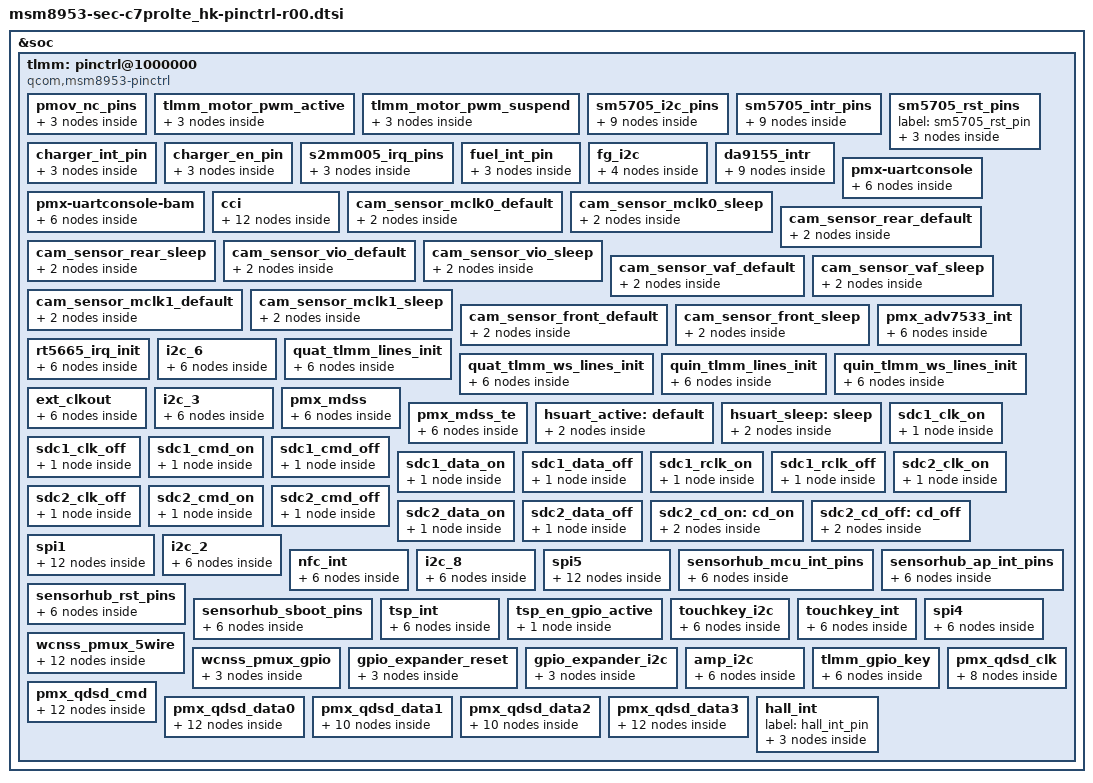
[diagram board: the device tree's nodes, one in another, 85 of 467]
/*
 * Copyright (c) 2015-2016, The Linux Foundation. All rights reserved.
 *
 * This program is free software; you can redistribute it and/or modify
 * it under the terms of the GNU General Public License version 2 and
 * only version 2 as published by the Free Software Foundation.
 *
 * This program is distributed in the hope that it will be useful,
 * but WITHOUT ANY WARRANTY; without even the implied warranty of
 * MERCHANTABILITY or FITNESS FOR A PARTICULAR PURPOSE.  See the
 * GNU General Public License for more details.
 */

&soc {
	tlmm: pinctrl@1000000 {
		compatible = "qcom,msm8953-pinctrl";
		reg = <0x1000000 0x300000>;
		interrupts = <0 208 0>;
		gpio-controller;
		#gpio-cells = <2>;
		interrupt-controller;
		#interrupt-cells = <2>;

		pmov_nc_pins {
			label = "pmov_nc_pins";
			qcom,num-grp-pins = <1>;
			qcom,pin-func = <0>;
			nc_gpio_default: default {
				mux {
					pins = "gpio126";
					function ="gpio";
				};
				config {
					pins = "gpio126";
					drive-strength = <2>; /* 2mA */
					bias-pull-down;
					input-enable;
				};
			};
		};
		
		tlmm_motor_pwm_active {
			qcom,num-grp-pins = <1>;
			qcom,pin-func = <2>;
			label = "motor_pwm_active";
			motor_pwm_active: motor_pwm_active {
				mux {
					pins = "gpio34";
					function = "gcc_gp1_clk_a";
				};
				config {
					pins = "gpio34";
					drive-strength = <2>;
					bias-disable;
					output-high;
				};
			};
		};

		tlmm_motor_pwm_suspend {
			qcom,num-grp-pins = <1>;
			qcom,pin-func = <0>;
			label = "motor_pwm_suspend";
			motor_pwm_suspend: motor_pwm_suspend {
				mux {
					pins = "gpio34";
					function = "gpio";
				};
				config {
					pins = "gpio34";
					drive-strength = <2>;
					bias-disable;
					output-low;
				};
			};
		};

		/* MUIC - SM5705 */
		sm5705_i2c_pins {
			qcom,num-grp-pins = <2>;
			qcom,pin-func = <0>;
			label = "sm5705_gpio";
			sm5705_i2c_default: default {
				mux {
					pins = "gpio73", "gpio74";
					function = "gpio";
				};
				config {
					pins = "gpio73", "gpio74";
					drive-strength = <2>;
					bias-disable;
				};
			};
			sm5705_i2c_active: active {
				mux {
					pins = "gpio73", "gpio74";
					function = "gpio";
				};
				config {
					pins = "gpio73", "gpio74";
					drive-strength = <2>;
					bias-disable;
				};

			};
			sm5705_i2c_suspend: suspend {
				mux {
					pins = "gpio73", "gpio74";
					function = "gpio";
				};
				config {
					pins = "gpio73", "gpio74";
					drive-strength = <2>;
					bias-disable;
				};
			};
		};

		sm5705_intr_pins {
			qcom,pin-func = <0>;
			label = "sm5705_gpio_int";
			sm5705_interrupt_default: default {
				mux {
					pins = "gpio63";
					function = "gpio";
				};
				config {
					pins = "gpio63";
					drive-strength = <2>;
					bias-disable;
				};
			};
			sm5705_interrupt_active: active {
				mux {
					pins = "gpio63";
					function = "gpio";
				};
				config {
					pins = "gpio63";
					drive-strength = <2>;
					bias-disable;
				};
			};
			sm5705_interrupt_suspend: suspend {
				mux {
					pins = "gpio63";
					function = "gpio";
				};
				config {
					pins = "gpio63";
					drive-strength = <2>;
					bias-disable;
				};
			};
		};

		sm5705_rst_pins {
			label = "sm5705_rst_pin";
			sm5705_rst_default: default {
				mux {
					pins = "gpio87";
					function = "gpio";
				};
				config {
					pins = "gpio87";
					drive-strength = <2>;
					bias-disable;
					output-high;
				};
			};
		};

		charger_int_pin {
			//qcom,pins = <&gp 61>;
			qcom,num-grp-pins = <1>;
			qcom,pin-func = <0>;
			label = "charger_int_gpio";
			charger_int_active: charger_int_active {
				mux {
					pins = "gpio61";
					function = "gpio";				
				};
				config {
					pins = "gpio61";
					drive-strength = <2>;
					bias-disable;         /* No PULL */
				};
			};
		};

		charger_en_pin {
			//qcom,pins = <&gp 132>;
			qcom,num-grp-pins = <1>;
			qcom,pin-func = <0>;
			label = "charger_en_gpio";
			charger_en_active: charger_en_active {
				mux {
					pins = "gpio132";
					function = "gpio";				
				};
				config {
					pins = "gpio132";
					drive-strength = <2>;
					bias-pull-down;
					output-low;
				};
			};
		};
		
		s2mm005_irq_pins {
			//qcom,pins = <&gp 141>;
			qcom,num-grp-pins = <1>;
			qcom,pin-func = <0>;
			label = "s2mm005_irq_default";
			s2mm005_irq_default: ccic_irq_default {
				mux {
					pins = "gpio141";
					function = "gpio";				
				};
				config {
					pins = "gpio141";
					drive-strength = <2>;
					bias-disable;         /* No PULL */
					input-enable;
				};
			};			
		};

		fuel_int_pin {
			//qcom,pins = <&gp 139>;
			qcom,num-grp-pins = <1>;
			qcom,pin-func = <0>;
			label = "fuel_int_gpio";
			fuel_int_active: fuel_int_active {
				mux {
					pins = "gpio139";
					function = "gpio";
				};
				config {
					pins = "gpio139";
					drive-strength = <2>;
					bias-disable;         /* No PULL */
					input-enable;
				};
			};
		};

		fg_i2c {
			/* CLK, DATA */
			//qcom,pins = <&gp 22>, <&gp 23>;
			qcom,num-grp-pins = <2>;
			qcom,pin-func = <0>;
			label = "fg_i2c";

			fg_i2c_active: fg_i2c_active {
				mux {
					pins = "gpio38", "gpio39";
					function = "gpio";
				};
				config {
					pins = "gpio38", "gpio39";
					drive-strength = <2>;	/* 2 MA */
					bias-disable; /* No PULL */
				};
			};

			fg_i2c_sleep: fg_i2c_sleep {
				drive-strength = <2>;	/* 2 MA */
				bias-disable; /* No PULL */
			};
		};

		da9155_intr {
			qcom,pin-func = <0>;
			label = "da9155_intr";
			da9155_intr_default: default {
				mux {
					pins = "gpio48";
					function = "gpio";
				};
				config {
					pins = "gpio48";
					drive-strength = <2>;
					bias-disable;
				};
			};
			da9155_intr_active: active {
				mux {
					pins = "gpio48";
					function = "gpio";
				};
				config {
					pins = "gpio48";
					drive-strength = <2>;
					bias-disable;
				};
			};
			da9155_intr_suspend: suspend {
				mux {
					pins = "gpio48";
					function = "gpio";
				};
				config {
					pins = "gpio48";
					drive-strength = <2>;
					bias-disable;
				};
			};
		};

		pmx-uartconsole {
			uart_console_active: uart_console_active {
				mux {
					pins = "gpio4", "gpio5";
					function = "blsp_uart2";
				};

				config {
					pins = "gpio4", "gpio5";
					drive-strength = <2>;
					bias-pull-down;
				};
			};

			uart_console_sleep: uart_console_sleep {
				mux {
					pins = "gpio4", "gpio5";
					function = "blsp_uart2";
				};

				config {
					pins = "gpio4", "gpio5";
					drive-strength = <2>;
					bias-pull-down;
				};
			};

		};

		pmx-uartconsole-bam {
			uart_console_bam_active: uart_console_bam_active {
				mux {
					pins = "gpio4", "gpio5";
					function = "blsp_uart2";
				};

				config {
					pins = "gpio4", "gpio5";
					drive-strength = <16>;
					bias-disable;
				};
			};

			uart_console_bam_sleep: uart_console_bam_sleep {
				mux {
					pins = "gpio4", "gpio5";
					function = "blsp_uart2";
				};

				config {
					pins = "gpio4", "gpio5";
					drive-strength = <2>;
					bias-disable;
				};
			};

		};
		
		cci {
			cci0_active: cci0_active {
				/* cci0 active state */
				mux {
					/* CLK, DATA */
					pins = "gpio29", "gpio30";
					function = "cci_i2c";
				};

				config {
					pins = "gpio29", "gpio30";
					drive-strength = <2>; /* 2 MA */
					bias-disable; /* No PULL */
				};
			};

			cci0_suspend: cci0_suspend {
				/* cci0 suspended state */
				mux {
					/* CLK, DATA */
					pins = "gpio29", "gpio30";
					function = "gpio";
				};

				config {
					pins = "gpio29", "gpio30";
					drive-strength = <2>; /* 2 MA */
					bias-disable; /* No PULL */
				};
			};

			cci1_active: cci1_active {
				/* cci1 active state */
				mux {
					/* CLK, DATA */
					pins = "gpio31", "gpio32";
					function = "cci_i2c";
				};

				config {
					pins = "gpio31", "gpio32";
					drive-strength = <2>; /* 2 MA */
					bias-disable; /* No PULL */
				};
			};

			cci1_suspend: cci1_suspend {
				/* cci1 suspended state */
				mux {
					/* CLK, DATA */
					pins = "gpio31", "gpio32";
					function = "gpio";
				};

				config {
					pins = "gpio31", "gpio32";
					drive-strength = <2>; /* 2 MA */
					bias-disable; /* No PULL */
				};
			};
		};
		
		/*sensors */
		cam_sensor_mclk0_default: cam_sensor_mclk0_default {
			/* MCLK0 */
			mux {
				/* CLK, DATA */
				pins = "gpio26";
				function = "cam_mclk";
			};

			config {
				pins = "gpio26";
				bias-disable; /* No PULL */
				drive-strength = <4>; /* 4 MA */
			};
		};

		cam_sensor_mclk0_sleep: cam_sensor_mclk0_sleep {
			/* MCLK0 */
			mux {
				/* CLK, DATA */
				pins = "gpio26";
				function = "gpio";
			};

			config {
				pins = "gpio26";
				bias-pull-down; /* PULL DOWN */
				drive-strength = <4>; /* 4 MA */
				output-low;
			};
		};

		cam_sensor_rear_default: cam_sensor_rear_default {
			/* RESET */
			mux {
				pins = "gpio40";
				function = "gpio";
			};

			config {
				pins = "gpio40";
				bias-pull-down; /* PULL DOWN */
				drive-strength = <2>; /* 2 MA */
				output-low;
			};
		};

		cam_sensor_rear_sleep: cam_sensor_rear_sleep {
			/* RESET */
			mux {
				pins = "gpio40";
				function = "gpio";
			};

			config {
				pins = "gpio40";
				bias-pull-down; /* PULL DOWN */
				drive-strength = <2>; /* 2 MA */
			};
		};

		cam_sensor_vio_default: cam_sensor_vio_default {
			/* VIO */
			mux {
				pins = "gpio134";
				function = "gpio";
			};

			config {
				pins = "gpio134";
				bias-pull-down; /* PULL DOWN */
				drive-strength = <2>; /* 2 MA */
				output-low;
			};
		};

		cam_sensor_vio_sleep: cam_sensor_vio_sleep {
			/* VDIO */
			mux {
				pins = "gpio134";
				function = "gpio";
			};

			config {
				pins = "gpio134";
				bias-pull-down; /* PULL DOWN */
				drive-strength = <2>; /* 2 MA */
				output-low;
			};
		};

		cam_sensor_vaf_default: cam_sensor_vaf_default {
			/* VAF */
			mux {
				pins = "gpio46";
				function = "gpio";
			};

			config {
				pins = "gpio46";
				bias-pull-down; /* PULL DOWN */
				drive-strength = <2>; /* 2 MA */
				output-low;
			};
		};

		cam_sensor_vaf_sleep: cam_sensor_vaf_sleep {
			/* VAF */
			mux {
				pins = "gpio46";
				function = "gpio";
			};

			config {
				pins = "gpio46";
				bias-pull-down; /* PULL DOWN */
				drive-strength = <2>; /* 2 MA */
				output-low;
			};
		};

		cam_sensor_mclk1_default: cam_sensor_mclk1_default {
			/* MCLK1 */
			mux {
				/* CLK, DATA */
				pins = "gpio27";
				function = "cam_mclk";
			};

			config {
				pins = "gpio27";
				bias-disable; /* No PULL */
				drive-strength = <4>; /* 4 MA */
			};
		};

		cam_sensor_mclk1_sleep: cam_sensor_mclk1_sleep {
			/* MCLK1 */
			mux {
				/* CLK, DATA */
				pins = "gpio27";
				function = "gpio";
			};

			config {
				pins = "gpio27";
				bias-pull-down; /* PULL DOWN */
				drive-strength = <4>; /* 4 MA */
				output-low;
			};
		};

		cam_sensor_front_default: cam_sensor_front_default {
			/* RESET*/
			mux {
				pins = "gpio129";
				function = "gpio";
			};

			config {
				pins = "gpio129";
				bias-pull-down; /* PULL DOWN */
				output-low;
				drive-strength = <2>; /* 2 MA */
			};
		};

		cam_sensor_front_sleep: cam_sensor_front_sleep {
			/* RESET */
			mux {
				pins = "gpio129";
				function = "gpio";
			};

			config {
				pins = "gpio129";
				bias-disable; /* No PULL */
				drive-strength = <2>; /* 2 MA */
			};
		};

		pmx_adv7533_int: pmx_adv7533_int {
			adv7533_int_active: adv7533_int_active {
				mux {
					pins = "gpio90";
					function = "gpio";
				};

				config {
					pins = "gpio90";
					drive-strength = <16>;
					bias-disable;
				};
			};

			adv7533_int_suspend: adv7533_int_suspend {
				mux {
					pins = "gpio90";
					function = "gpio";
				};

				config {
					pins = "gpio90";
					drive-strength = <16>;
					bias-disable;
				};
			};

		};

		rt5665_irq_init: rt5665_irq_init {
			rt5665_irq_active: rt5665_irq_active {
				mux {
					pins = "gpio62";
					function = "gpio";
				};
				config {
					pins = "gpio62";
					drive-strength = <2>;
					bias-disable;
				};
			};
			rt5665_irq_suspend: rt5665_irq_suspend {
				mux {
					pins = "gpio62";
					function = "gpio";
				};
				config {
					pins = "gpio62";
					drive-strength = <2>;
					bias-disable;
				};
			};
		};

		i2c_6 {
			i2c_6_active: i2c_6_active {
				/* active state */
				mux {
					pins = "gpio22", "gpio23";
					function = "blsp_i2c6";
				};
				config {
					pins = "gpio22", "gpio23";
					drive-strength = <2>;
					bias-disable;
				};
			};

			i2c_6_sleep: i2c_6_sleep {
				/* suspended state */
				mux {
					pins = "gpio22", "gpio23";
					function = "blsp_i2c6";
				};

				config {
					pins = "gpio22", "gpio23";
					drive-strength = <2>;
					bias-disable;
				};
			};
		};
		
		quat_tlmm_lines_init: quat_tlmm_lines_init {
			quat_tlmm_lines_act: quat_tlmm_lines_act {
				mux {
					pins = "gpio135", "gpio138", "gpio137";
					function = "sec_mi2s";
				};
				config {
					pins = "gpio135", "gpio138", "gpio137";
					drive-strength = <4>;
					bias-disable;
				};
			};
			quat_tlmm_lines_sus: quat_tlmm_lines_sus {
				mux {
					pins = "gpio135", "gpio138", "gpio137";
					function = "sec_mi2s";
				};
				config {
					pins = "gpio135", "gpio138", "gpio137";
					drive-strength = <2>;
					bias-disable;
				};
			};
		};
		
		quat_tlmm_ws_lines_init: quat_tlmm_ws_lines_init {
			quat_tlmm_ws_lines_act: quat_tlmm_ws_lines_act {
				mux {
					pins = "gpio136";
					function = "sec_mi2s";
				};
				config {
					pins = "gpio136";
					drive-strength = <4>;
					bias-disable;
				};
			};
			quat_tlmm_ws_lines_sus: quat_tlmm_ws_lines_sus {
				mux {
					pins = "gpio136";
					function = "sec_mi2s";
				};
				config {
					pins = "gpio136";
					drive-strength = <2>;
					bias-disable;
				};
			};
		};		

		quin_tlmm_lines_init: quin_tlmm_lines_init {
			quin_tlmm_lines_act: quin_tlmm_lines_act {
				mux {
					pins = "gpio91", "gpio93", "gpio88";
					function = "pri_mi2s";
				};
				config {
					pins = "gpio91", "gpio93", "gpio88";
					drive-strength = <4>;
					bias-disable;
				};
			};
			quin_tlmm_lines_sus: quin_tlmm_lines_sus {
				mux {
					pins = "gpio91", "gpio93", "gpio88";
					function = "pri_mi2s";
				};
				config {
					pins = "gpio91", "gpio93", "gpio88";
					drive-strength = <2>;
					bias-disable;
				};
			};
		};
		
		quin_tlmm_ws_lines_init: quin_tlmm_ws_lines_init {
			quin_tlmm_ws_lines_act: quin_tlmm_ws_lines_act {
				mux {
					pins = "gpio92";
					function = "pri_mi2s_ws";
				};
				config {
					pins = "gpio92";
					drive-strength = <4>;
					bias-disable;
				};
			};
			quin_tlmm_ws_lines_sus: quin_tlmm_ws_lines_sus {
				mux {
					pins = "gpio92";
					function = "pri_mi2s_ws";
				};
				config {
					pins = "gpio92";
					drive-strength = <2>;
					bias-disable;
				};
			};
		};		

		ext_clkout: ext_clkout {
			gp_clk0_active: gp_clk0_active {
				mux {
					pins = "gpio33";
					function = "gcc_gp0_clk_a";
				};
				config {
					pins = "gpio33";
					drive-strength = <8>;
					bias-disable;
					output-high;
				};
			};
			gp_clk0_suspend: gp_clk0_suspend {
				mux {
					pins = "gpio33";
					function = "gcc_gp0_clk_a";
				};
				config {
					pins = "gpio33";
					drive-strength = <2>;
					bias-disable;
					output-low;
				};
			};
		};

		i2c_3 {
			i2c_3_active: i2c_3_active {
				/* active state */
				mux {
					pins = "gpio10", "gpio11";
					function = "blsp_i2c3";
				};

				config {
					pins = "gpio10", "gpio11";
					drive-strength = <2>;
					bias-disable;
				};
			};

			i2c_3_sleep: i2c_3_sleep {
				/* suspended state */
				mux {
					pins = "gpio10", "gpio11";
					function = "blsp_i2c3";
				};

				config {
					pins = "gpio10", "gpio11";
					drive-strength = <2>;
					bias-disable;
				};
			};
		};

		pmx_mdss: pmx_mdss {
			mdss_dsi_active: mdss_dsi_active {
				mux {
					pins = "gpio50", "gpio94";	// LCD_RST & LCD_LDO_EN
					function = "gpio";
				};

				config {
					pins = "gpio50", "gpio94";
					drive-strength = <8>; /* 8 mA */
					bias-disable;
				};
			};

			mdss_dsi_suspend: mdss_dsi_suspend {
				mux {
					pins = "gpio50", "gpio94";
					function = "gpio";
				};

				config {
					pins = "gpio50", "gpio94";
					drive-strength = <2>; /* 2 mA */
					bias-pull-down; /* pull down */
				};
			};
		};

		pmx_mdss_te {
			mdss_te_active: mdss_te_active {
				mux {
					pins = "gpio24";
					function = "mdp_vsync";
				};
				config {
					pins = "gpio24";
					drive-strength = <2>; /* 8 mA */
					bias-pull-down; /* pull down*/
				};
			};

			mdss_te_suspend: mdss_te_suspend {
				mux {
					pins = "gpio24";
					function = "mdp_vsync";
				};
				config {
					pins = "gpio24";
					drive-strength = <2>; /* 2 mA */
					bias-pull-down; /* pull down */
				};
			};
		};

		hsuart_active: default {
			mux {
				pins = "gpio12", "gpio13", "gpio14", "gpio15";
				function = "blsp_uart4";
			};

			config {
				pins = "gpio12", "gpio13", "gpio14", "gpio15";
				drive-strength = <16>;
				bias-disable;
			};
		};

		hsuart_sleep: sleep {
			mux {
				pins = "gpio12", "gpio13", "gpio14", "gpio15";
				function = "gpio";
			};

			config {
				pins = "gpio12", "gpio13", "gpio14", "gpio15";
				drive-strength = <2>;
				bias-disable;
			};
		};

		/* SDC pin type */
		sdc1_clk_on: sdc1_clk_on {
			config {
				pins = "sdc1_clk";
				bias-disable;		/* NO pull */
				drive-strength = <16>;	/* 16 MA */
			};
		};

		sdc1_clk_off: sdc1_clk_off {
			config {
				pins = "sdc1_clk";
				bias-disable;		/* NO pull */
				drive-strength = <2>;	/* 2 MA */
			};
		};

		sdc1_cmd_on: sdc1_cmd_on {
			config {
				pins = "sdc1_cmd";
				bias-pull-up;		/* pull up */
				drive-strength = <10>;	/* 10 MA */
			};
		};

		sdc1_cmd_off: sdc1_cmd_off {
			config {
				pins = "sdc1_cmd";
				num-grp-pins = <1>;
				bias-pull-up;		/* pull up */
				drive-strength = <2>;	/* 2 MA */
			};
		};

		sdc1_data_on: sdc1_data_on {
			config {
				pins = "sdc1_data";
				bias-pull-up;		/* pull up */
				drive-strength = <10>;	/* 10 MA */
			};
		};

		sdc1_data_off: sdc1_data_off {
			config {
				pins = "sdc1_data";
				bias-pull-up;		/* pull up */
				drive-strength = <2>;	/* 2 MA */
			};
		};

		sdc1_rclk_on: sdc1_rclk_on {
			config {
				pins = "sdc1_rclk";
				bias-pull-down; /* pull down */
			};
		};

		sdc1_rclk_off: sdc1_rclk_off {
			config {
				pins = "sdc1_rclk";
				bias-pull-down; /* pull down */
			};
		};

		sdc2_clk_on: sdc2_clk_on {
			config {
				pins = "sdc2_clk";
				drive-strength = <14>; /* 14 MA */
				bias-disable; /* NO pull */
			};
		};

		sdc2_clk_off: sdc2_clk_off {
			config {
				pins = "sdc2_clk";
				bias-disable; /* NO pull */
				drive-strength = <2>; /* 2 MA */
			};
		};

		sdc2_cmd_on: sdc2_cmd_on {
			config {
				pins = "sdc2_cmd";
				bias-pull-up; /* pull up */
				drive-strength = <10>; /* 10 MA */
			};
		};

		sdc2_cmd_off: sdc2_cmd_off {
			config {
				pins = "sdc2_cmd";
				bias-pull-up; /* pull up */
				drive-strength = <2>; /* 2 MA */
			};
		};

		sdc2_data_on: sdc2_data_on {
			config {
				pins = "sdc2_data";
				bias-pull-up; /* pull up */
				drive-strength = <10>; /* 10 MA */
			};
		};

		sdc2_data_off: sdc2_data_off {
			config {
				pins = "sdc2_data";
				bias-pull-up; /* pull up */
				drive-strength = <2>; /* 2 MA */
			};
		};

		/delete-node/ cd_on;
		sdc2_cd_on: cd_on {
			mux {
				pins = "gpio133";
				function = "gpio";
			};

			config {
				pins = "gpio133";
				drive-strength = <2>;
				bias-disable;
			};
		};

		sdc2_cd_off: cd_off {
			mux {
				pins = "gpio133";
				function = "gpio";
			};

			config {
				pins = "gpio133";
				drive-strength = <2>;
				bias-disable;
			};
		};

		spi1 {
			spi1_default: spi1_default {
				/* active state */
				mux {
					/* MOSI, MISO, CLK */
					pins = "gpio0", "gpio1", "gpio3";
					function = "blsp_spi1";
				};

				config {
					pins = "gpio0", "gpio1", "gpio2";
					drive-strength = <12>; /* 12 MA */
					bias-disable = <0>; /* No PULL */
				};
			};

			spi1_sleep: spi1_sleep {
				/* suspended state */
				mux {
					/* MOSI, MISO, CLK */
					pins = "gpio0", "gpio1", "gpio3";
					function = "gpio";
				};

				config {
					pins = "gpio0", "gpio1", "gpio3";
					drive-strength = <2>; /* 2 MA */
					bias-pull-down; /* PULL Down */
				};
			};

			spi1_cs0_active: cs0_active {
				/* CS */
				mux {
					pins = "gpio2";
					function = "blsp_spi1";
				};

				config {
					pins = "gpio2";
					drive-strength = <2>;
					bias-disable = <0>;
				};
			};

			spi1_cs0_sleep: cs0_sleep {
				/* CS */
				mux {
					pins = "gpio2";
					function = "gpio";
				};

				config {
					pins = "gpio2";
					drive-strength = <2>;
					bias-disable = <0>;
				};
			};
		};

		i2c_2 {
			i2c_2_active: i2c_2_active {
				/* active state */
				mux {
					pins = "gpio6", "gpio7";
					function = "blsp_i2c2";
				};

				config {
					pins = "gpio6", "gpio7";
					drive-strength = <2>;
					bias-disable;
				};
			};

			i2c_2_sleep: i2c_2_sleep {
				/* suspended state */
				mux {
					pins = "gpio6", "gpio7";
					function = "blsp_i2c2";
				};

				config {
					pins = "gpio6", "gpio7";
					drive-strength = <2>;
					bias-disable;
				};
			};
		};

		nfc_int{
			nfc_int_active: nfc_int_active {
				mux {
					pins = "gpio21";
					function = "gpio";
				};

				config {
					pins = "gpio21";
					drive-strength = <2>; 
					bias-pull-down;
				};
			};

			nfc_int_suspend: suspend  {
				mux {
					pins = "gpio21";
					function = "gpio";
				};
				config {
					pins = "gpio21";
					drive-strength = <2>; 
					bias-pull-down;
				};
			};
		};

		i2c_8 {
			i2c_8_active: i2c_8_active {
				/* active state */
				mux {
					pins = "gpio98", "gpio99";
					function = "blsp_i2c8";
				};

				config {
					pins = "gpio98", "gpio99";
					drive-strength = <2>;
					bias-disable;
				};
			};

			i2c_8_suspend: i2c_8_suspend {
				/* suspended state */
				mux {
					pins = "gpio98", "gpio99";
					function = "blsp_i2c8";
				};

				config {
					pins = "gpio98", "gpio99";
					drive-strength = <2>;
					bias-disable;
				};
			};
		};

		spi5 {
			spi_5_active: spi_5_active {
				mux {
					pins = "gpio16", "gpio17", "gpio19";
					function = "blsp_spi5";
				};

				config {
					pins = "gpio16", "gpio17", "gpio19";
					drive-strength = <2>;
					bias-pull-up;
				};
			};

			spi_5_sleep: spi_5_sleep {
				mux {
					pins = "gpio16", "gpio17", "gpio19";
					function = "blsp_spi5";
				};

				config {
					pins = "gpio16", "gpio17", "gpio19";
					drive-strength = <2>;
					bias-pull-down;
				};
			};
			
			spi5_cs0_active: spi5_cs0_active {
				/* CS */
				mux {
					pins = "gpio18";
					function = "blsp_spi5";
				};

				config {
					pins = "gpio18";
					drive-strength = <2>;
					bias-disable = <0>;
				};
			};

			spi5_cs0_sleep: spi5_cs0_sleep {
				/* CS */
				mux {
					pins = "gpio18";
					function = "gpio";
				};

				config {
					pins = "gpio18";
					drive-strength = <2>;
					bias-disable = <0>;
				};
			};
		};

sensorhub_mcu_int_pins { /* MCU_INT1, MCU_INT2 */
			qcom,num-grp-pins = <2>;
			qcom,pin-func = <0>;
			label = "sensorhub_mcu_int_pins";

			sensorhub_mcu_int_default: sensorhub_mcu_int_default {
				mux {
					pins =  "gpio42", "gpio46";
					function = "gpio";
				};

				config {
					pins =  "gpio42", "gpio46";
					drive-strength = <2>;
					bias-disable;  /* no pull */ /* In */
					input-high;
				};
			};
			sensorhub_mcu_int_sleep: sensorhub_mcu_int_sleep {
				mux {
					pins =  "gpio42", "gpio46";
					function = "gpio";
				};

				config {
					pins =  "gpio42", "gpio46";
					drive-strength = <2>;
					bias-disable;  /* no pull */ /* In */
					input-high;
				};
			};
		};

		sensorhub_ap_int_pins { /* AP_INT */
			qcom,num-grp-pins = <1>;
			qcom,pin-func = <0>;
			label = "sensorhub_ap_int_pins";

			sensorhub_ap_int_default: sensorhub_ap_int_default {
				mux {
					pins =  "gpio43";
					function = "gpio";
				};

				config {
					pins =  "gpio43";
					drive-strength = <8>;
					bias-disable;  /* no pull */
					output-high;   /* Out */
				};
			};
			sensorhub_ap_int_sleep: sensorhub_ap_int_sleep {
				mux {
					pins =  "gpio43";
					function = "gpio";
				};

				config {
					pins =  "gpio43";
					drive-strength = <8>;
					bias-disable;  /* no pull */
					output-high;   /* Out */
				};
			};
		};

		sensorhub_rst_pins { /* RST */
			qcom,num-grp-pins = <1>;
			qcom,pin-func = <0>;
			label = "sensorhub_rst_pins";

			sensorhub_rst_default: sensorhub_rst_default {
				mux {
					pins =  "gpio72";
					function = "gpio";
				};

				config {
					pins =  "gpio72";
					drive-strength = <8>;
					bias-disable;  /* no pull */
					output-high;   /* Out */
				};
			};
			sensorhub_rst_sleep: sensorhub_rst_sleep {
				mux {
					pins =  "gpio72";
					function = "gpio";
				};

				config {
					pins =  "gpio72";
					drive-strength = <8>;
					bias-disable;  /* no pull */ 
					output-high;   /* Out */
				};
			};
		};

		sensorhub_sboot_pins { /* SBOOT */
			qcom,num-grp-pins = <1>;
			qcom,pin-func = <0>;
			label = "sensorhub_sboot_pins";

			sensorhub_sboot_default: sensorhub_sboot_default {
				mux {
					pins =  "gpio20";
					function = "gpio";
				};

				config {
					pins =  "gpio20";
					drive-strength = <8>;
					bias-disable;  /* no pull */
					output-high;   /* Out */
				};
			};
			sensorhub_sboot_sleep: sensorhub_sboot_sleep {
				mux {
					pins =  "gpio20";
					function = "gpio";
				};

				config {
					pins =  "gpio20";
					drive-strength = <8>;
					bias-disable;  /* no pull */ 
					output-high;   /* Out */
				};
			};
		};

		tsp_int {
			/*qcom,pins = <&gp 59>;*/ /* INTERRUPT */
			pins = "gpio59";
			qcom,num-grp-pins = <1>;
			qcom,pin-func = <0>;
			label = "tsp_int";
			tsp_int_active: tsp_int_active {
				mux {
					pins = "gpio59";
					function = "gpio";
				};
				config {
					pins = "gpio59";
					drive-strength = <2>;
					bias-disable;
				};
			};
			tsp_int_suspend: tsp_int_suspend {
				mux {
					pins = "gpio59";
					function = "gpio";
				};
				config {
					pins = "gpio59";
					drive-strength = <2>;
					bias-disable;
				};
			};
		};

		tsp_en_gpio_active {
			pins = "gpio95";
			qcom,num-grp-pins = <1>;
			qcom,pin-func = <0>;
			label = "tsp_en_gpio";
			tsp_en_active: tsp_en_active {
			drive-strength = <2>;
			bias-pull-down; /* PULL DOWN*/
			};
		};

		touchkey_i2c {
			/*qcom,pins = <&gp 16>, <&gp 17>;*/ /* SDA, SCL */
			pins = "gpio36", "gpio66"; /* SCL, SDA */
			qcom,num-grp-pins = <2>;
			qcom,pin-func = <0>;
			label = "touchkey_i2c";
			touchkey_i2c_active: touchkey_i2c_active {
				mux {
					pins = "gpio36", "gpio66";
					function = "gpio";
				};
				config {
					pins = "gpio36", "gpio66";
					drive-strength = <2>;
					bias-disable;
				};
			};
			touchkey_i2c_suspend: touchkey_i2c_suspend {
				mux {
					pins = "gpio36", "gpio66";
					function = "gpio";
				};
				config {
					pins = "gpio36", "gpio66";
					drive-strength = <2>;
					bias-disable;
				};
			};
		};

		touchkey_int {
			/*qcom,pins = <&gp 60>;*/ /* INTERRUPT */
			pins = "gpio60";
			qcom,num-grp-pins = <1>;
			qcom,pin-func = <0>;
			label = "touchkey_int";
			touchkey_int_active: touchkey_int_active {
				mux {
					pins = "gpio60";
					funtion = "gpio";
				};
				config {
					pins = "gpio60";
					drive-strength = <2>;
					bias-disable = <0>; /* No PULL */
				};
			};
			touchkey_int_suspend: touchkey_int_suspend {
				mux {
					pins = "gpio60";
					funtion = "gpio";
				};
				config {
					pins = "gpio60";
					drive-strength = <2>;
					bias-disable = <0>; /* No PULL */
				};
			};
		};

		spi4 {
			spi_4_active: spi_4_active {
				mux {
					pins = "gpio12", "gpio13", "gpio14", "gpio15";
					function = "blsp_spi4";
				};

				config {
					pins = "gpio12", "gpio13", "gpio14", "gpio15";
					drive-strength = <2>;
					bias-pull-up;
				};
			};

			spi_4_sleep: spi_4_sleep {
				mux {
					pins = "gpio12", "gpio13", "gpio14", "gpio15";
					function = "gpio";
				};

				config {
					pins = "gpio12", "gpio13", "gpio14", "gpio15";
					drive-strength = <2>;
					bias-pull-down;
				};
			};
		};

		wcnss_pmux_5wire {
			/* Active configuration of bus pins */
			wcnss_default: wcnss_default {
				wcss_wlan2 {
					pins = "gpio76";
					function = "wcss_wlan2";
				};
				wcss_wlan1 {
					pins = "gpio77";
					function = "wcss_wlan1";
				};
				wcss_wlan0 {
					pins = "gpio78";
					function = "wcss_wlan0";
				};
				wcss_wlan {
					pins = "gpio79", "gpio80";
					function = "wcss_wlan";
				};

				config {
					pins = "gpio76", "gpio77",
						"gpio78", "gpio79",
						"gpio80";
					drive-strength = <6>; /* 6 MA */
					bias-pull-up; /* PULL UP */
				};
			};

			wcnss_sleep: wcnss_sleep {
				wcss_wlan2 {
					pins = "gpio76";
					function = "wcss_wlan2";
				};
				wcss_wlan1 {
					pins = "gpio77";
					function = "wcss_wlan1";
				};
				wcss_wlan0 {
					pins = "gpio78";
					function = "wcss_wlan0";
				};
				wcss_wlan {
					pins = "gpio79", "gpio80";
					function = "wcss_wlan";
				};

				config {
					pins = "gpio76", "gpio77",
						"gpio78", "gpio79",
						"gpio80";
					drive-strength = <2>; /* 2 MA */
					bias-pull-down; /* PULL Down */
				};
			};
		};

		wcnss_pmux_gpio: wcnss_pmux_gpio {
			wcnss_gpio_default: wcnss_gpio_default {
				/* Active configuration of bus pins */
				mux {
					/* Uses general purpose pins */
					pins = "gpio76", "gpio77",
					"gpio78", "gpio79",
					"gpio80";
					function = "gpio";
				};

				config {
					pins = "gpio76", "gpio77",
						"gpio78", "gpio79",
						"gpio80";
					drive-strength = <6>; /* 6 MA */
					bias-pull-up; /* PULL UP */
				};
			};
		};
		
		gpio_expander_reset {
			qcom,num-grp-pins = <1>;
			qcom,pin-func = <0>;
			label = "gpio_expander_reset";
			expander_reset_active: default {
				mux {
					pins = "gpio96";
					function = "gpio";
				};
				config {
					pins = "gpio96";
					drive-strength = <2>;
					bias-disable = <0>; /* No PULL */
				};
			};
		};

		gpio_expander_i2c {
			qcom,num-grp-pins = <2>;
			qcom,pin-func = <0>;
			label = "gpio_expander_i2c";
			expander_i2c_active: default {
				mux {
					pins = "gpio128", "gpio131";
					function = "gpio";
				};
				config {
					pins = "gpio128", "gpio131";
					drive-strength = <2>;
					bias-disable = <0>; /* No PULL */
				};			
			};
		};			

		amp_i2c {
			qcom,num-grp-pins = <2>;
			qcom,pin-func = <0>;
			label = "amp_i2c";
			i2c_25_active: i2c_25_active {
				mux {
					pins = "gpio65", "gpio64";
					function = "gpio";
				};
				config {
					pins = "gpio65", "gpio64";
					drive-strength = <2>;
					bias-disable;
				};
			};
			i2c_25_sleep: i2c_25_sleep {
				mux {
					pins = "gpio65", "gpio64";
					function = "gpio";
				};
				config {
					pins = "gpio65", "gpio64";
					drive-strength = <2>;
					bias-pull-down;
				};
			};
		};

		tlmm_gpio_key {
			gpio_key_active: gpio_key_active {
				mux {
					pins = "gpio85", "gpio86";
					function = "gpio";
				};

				config {
					pins = "gpio85", "gpio86";
					drive-strength = <2>;
					bias-pull-up;
				};
			};

			gpio_key_suspend: gpio_key_suspend {
				mux {
					pins = "gpio85", "gpio86";
					function = "gpio";
				};

				config {
					pins = "gpio85", "gpio86";
					drive-strength = <2>;
					bias-pull-up;
				};
			};
		};
		pmx_qdsd_clk {
			qdsd_clk_sdcard: clk_sdcard {
				config {
					pins = "qdsd_clk";
					bias-disable;/* NO pull */
					drive-strength = <16>; /* 16 MA */
				};
			};
			qdsd_clk_trace: clk_trace {
				config {
					pins = "qdsd_clk";
					bias-pull-down; /* pull down */
					drive-strength = <2>; /* 2 MA */
				};
			};
			qdsd_clk_swdtrc: clk_swdtrc {
				config {
					pins = "qdsd_clk";
					bias-pull-down; /* pull down */
					drive-strength = <2>; /* 2 MA */
				};
			};
			qdsd_clk_spmi: clk_spmi {
				config {
					pins = "qdsd_clk";
					bias-pull-down; /* pull down */
					drive-strength = <2>; /* 2 MA */
				};
			};
		};

		pmx_qdsd_cmd {
			qdsd_cmd_sdcard: cmd_sdcard {
				config {
					pins = "qdsd_cmd";
					bias-pull-down; /* pull down */
					drive-strength = <8>; /* 8 MA */
				};
			};
			qdsd_cmd_trace: cmd_trace {
				config {
					pins = "qdsd_cmd";
					bias-pull-down; /* pull down */
					drive-strength = <2>; /* 2 MA */
				};
			};
			qdsd_cmd_swduart: cmd_uart {
				config {
					pins = "qdsd_cmd";
					bias-pull-up; /* pull up */
					drive-strength = <2>; /* 2 MA */
				};
			};
			qdsd_cmd_swdtrc: cmd_swdtrc {
				config {
					pins = "qdsd_cmd";
					bias-pull-up; /* pull up */
					drive-strength = <2>; /* 2 MA */
				};
			};
			qdsd_cmd_jtag: cmd_jtag {
				config {
					pins = "qdsd_cmd";
					bias-disable; /* NO pull */
					drive-strength = <8>; /* 8 MA */
				};
			};
			qdsd_cmd_spmi: cmd_spmi {
				config {
					pins = "qdsd_cmd";
					bias-pull-down; /* pull down */
					drive-strength = <10>; /* 10 MA */
				};
			};
		};

		pmx_qdsd_data0 {
			qdsd_data0_sdcard: data0_sdcard {
				config {
					pins = "qdsd_data0";
					bias-pull-down; /* pull down */
					drive-strength = <8>; /* 8 MA */
				};
			};
			qdsd_data0_trace: data0_trace {
				config {
					pins = "qdsd_data0";
					bias-pull-down; /* pull down */
					drive-strength = <8>; /* 8 MA */
				};
			};
			qdsd_data0_swduart: data0_uart {
				config {
					pins = "qdsd_data0";
					bias-pull-down; /* pull down */
					drive-strength = <2>; /* 2 MA */
				};
			};
			qdsd_data0_swdtrc: data0_swdtrc {
				config {
					pins = "qdsd_data0";
					bias-pull-down; /* pull down */
					drive-strength = <2>; /* 2 MA */
				};
			};
			qdsd_data0_jtag: data0_jtag {
				config {
					pins = "qdsd_data0";
					bias-pull-up; /* pull up */
					drive-strength = <2>; /* 2 MA */
				};
			};
			qdsd_data0_spmi: data0_spmi {
				config {
					pins = "qdsd_data0";
					bias-pull-down; /* pull down */
					drive-strength = <2>; /* 2 MA */
				};
			};
		};

		pmx_qdsd_data1 {
			qdsd_data1_sdcard: data1_sdcard {
				config {
					pins = "qdsd_data1";
					bias-pull-down; /* pull down */
					drive-strength = <8>; /* 8 MA */
				};
			};
			qdsd_data1_trace: data1_trace {
				config {
					pins = "qdsd_data1";
					bias-pull-down; /* pull down */
					drive-strength = <8>; /* 8 MA */
				};
			};
			qdsd_data1_swduart: data1_uart {
				config {
					pins = "qdsd_data1";
					bias-pull-down; /* pull down */
					drive-strength = <2>; /* 2 MA */
				};
			};
			qdsd_data1_swdtrc: data1_swdtrc {
				config {
					pins = "qdsd_data1";
					bias-pull-down; /* pull down */
					drive-strength = <2>; /* 2 MA */
				};
			};
			qdsd_data1_jtag: data1_jtag {
				config {
					pins = "qdsd_data1";
					bias-pull-down; /* pull down */
					drive-strength = <2>; /* 2 MA */
				};
			};
		};

		pmx_qdsd_data2 {
			qdsd_data2_sdcard: data2_sdcard {
				config {
					pins = "qdsd_data2";
					bias-pull-down; /* pull down */
					drive-strength = <8>; /* 8 MA */
				};
			};
			qdsd_data2_trace: data2_trace {
				config {
					pins = "qdsd_data2";
					bias-pull-down; /* pull down */
					drive-strength = <8>; /* 8 MA */
				};
			};
			qdsd_data2_swduart: data2_uart {
				config {
					pins = "qdsd_data2";
					bias-pull-down; /* pull down */
					drive-strength = <2>; /* 2 MA */
				};
			};
			qdsd_data2_swdtrc: data2_swdtrc {
				config {
					pins = "qdsd_data2";
					bias-pull-down; /* pull down */
					drive-strength = <2>; /* 2 MA */
				};
			};
			qdsd_data2_jtag: data2_jtag {
				config {
					pins = "qdsd_data2";
					bias-pull-up; /* pull up */
					drive-strength = <8>; /* 8 MA */
				};
			};
		};

		pmx_qdsd_data3 {
			qdsd_data3_sdcard: data3_sdcard {
				config {
					pins = "qdsd_data3";
					bias-pull-down; /* pull down */
					drive-strength = <8>; /* 8 MA */
				};
			};
			qdsd_data3_trace: data3_trace {
				config {
					pins = "qdsd_data3";
					bias-pull-down; /* pull down */
					drive-strength = <8>; /* 8 MA */
				};
			};
			qdsd_data3_swduart: data3_uart {
				config {
					pins = "qdsd_data3";
					bias-pull-up; /* pull up */
					drive-strength = <2>; /* 2 MA */
				};
			};
			qdsd_data3_swdtrc: data3_swdtrc {
				config {
					pins = "qdsd_data3";
					bias-pull-up; /* pull up */
					drive-strength = <2>; /* 2 MA */
				};
			};
			qdsd_data3_jtag: data3_jtag {
				config {
					pins = "qdsd_data3";
					bias-pull-up; /* pull up */
					drive-strength = <2>; /* 2 MA */
				};
			};
			qdsd_data3_spmi: data3_spmi {
				config {
					pins = "qdsd_data3";
					bias-pull-down; /* pull down */
					drive-strength = <8>; /* 8 MA */
				};
			};
		};

		hall_int {
			label = "hall_int_pin";
			hall_int_default: default {
				mux {
					pins = "gpio44";
					function = "gpio";
				};
				config {
					pins = "gpio44";
					drive-strength = <2>;
					bias-disable;
				};
			};
		};
	};
};
